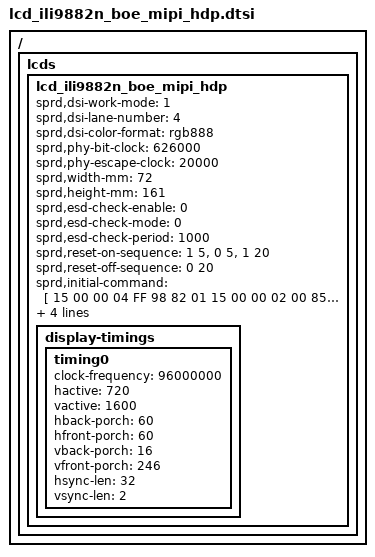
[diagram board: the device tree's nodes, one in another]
/ { lcds {
    lcd_ili9882n_boe_mipi_hdp: lcd_ili9882n_boe_mipi_hdp {

        sprd,dsi-work-mode = <1>;
        sprd,dsi-lane-number = <4>;
        sprd,dsi-color-format = "rgb888";

        sprd,phy-bit-clock = <626000>;
        sprd,phy-escape-clock = <20000>;

        sprd,width-mm = <72>;
        sprd,height-mm = <161>;

        sprd,esd-check-enable = <0>;
        sprd,esd-check-mode = <0>;
        sprd,esd-check-period = <1000>;

        sprd,reset-on-sequence = <1 5>, <0 5>, <1 20>;
        sprd,reset-off-sequence = <0 20>;

        sprd,initial-command = [

            15  00  00  04 FF 98 82 01
            15  00  00  02 00 85
            15  00  00  02 01 32
            15  00  00  02 02 2A
            15  00  00  02 03 05
            15  00  00  02 04 C9
            15  00  00  02 05 32
            15  00  00  02 06 2A
            15  00  00  02 07 05
            15  00  00  02 08 85
            15  00  00  02 09 02
            15  00  00  02 0A 72
            15  00  00  02 0B 00
            15  00  00  02 28 00
            15  00  00  02 29 00
            15  00  00  02 EE 17
            15  00  00  02 2A 85
            15  00  00  02 2B 4A
            15  00  00  02 F0 37
            15  00  00  02 E0 7E
            15  00  00  02 31 07
            15  00  00  02 32 07
            15  00  00  02 33 07
            15  00  00  02 34 07
            15  00  00  02 35 00
            15  00  00  02 36 07
            15  00  00  02 37 01
            15  00  00  02 38 22
            15  00  00  02 39 23
            15  00  00  02 3A 07
            15  00  00  02 3B 10
            15  00  00  02 3C 12
            15  00  00  02 3D 14
            15  00  00  02 3E 16
            15  00  00  02 3F 07
            15  00  00  02 40 0C
            15  00  00  02 41 0E
            15  00  00  02 42 07
            15  00  00  02 43 07
            15  00  00  02 44 07
            15  00  00  02 45 07
            15  00  00  02 46 07
            15  00  00  02 47 07
            15  00  00  02 48 07
            15  00  00  02 49 07
            15  00  00  02 4A 07
            15  00  00  02 4B 00
            15  00  00  02 4C 07
            15  00  00  02 4D 01
            15  00  00  02 4E 22
            15  00  00  02 4F 23
            15  00  00  02 50 07
            15  00  00  02 51 11
            15  00  00  02 52 13
            15  00  00  02 53 15
            15  00  00  02 54 17
            15  00  00  02 55 07
            15  00  00  02 56 0D
            15  00  00  02 57 0F
            15  00  00  02 58 07
            15  00  00  02 59 07
            15  00  00  02 5A 07
            15  00  00  02 5B 07
            15  00  00  02 5C 07
            15  00  00  02 61 07
            15  00  00  02 62 07
            15  00  00  02 63 07
            15  00  00  02 64 07
            15  00  00  02 65 00
            15  00  00  02 66 07
            15  00  00  02 67 01
            15  00  00  02 68 22
            15  00  00  02 69 23
            15  00  00  02 6A 07
            15  00  00  02 6B 17
            15  00  00  02 6C 15
            15  00  00  02 6D 13
            15  00  00  02 6E 11
            15  00  00  02 6F 07
            15  00  00  02 70 0F
            15  00  00  02 71 0D
            15  00  00  02 72 07
            15  00  00  02 73 07
            15  00  00  02 74 07
            15  00  00  02 75 07
            15  00  00  02 76 07
            15  00  00  02 77 07
            15  00  00  02 78 07
            15  00  00  02 79 07
            15  00  00  02 7A 07
            15  00  00  02 7B 00
            15  00  00  02 7C 07
            15  00  00  02 7D 01
            15  00  00  02 7E 22
            15  00  00  02 7F 23
            15  00  00  02 80 07
            15  00  00  02 81 16
            15  00  00  02 82 14
            15  00  00  02 83 12
            15  00  00  02 84 10
            15  00  00  02 85 07
            15  00  00  02 86 0E
            15  00  00  02 87 0C
            15  00  00  02 88 07
            15  00  00  02 89 07
            15  00  00  02 8A 07
            15  00  00  02 8B 07
            15  00  00  02 8C 07
            15  00  00  02 A0 01
            15  00  00  02 A1 00
            15  00  00  02 A2 00
            15  00  00  02 A3 00
            15  00  00  02 A4 00
            15  00  00  02 A7 00
            15  00  00  02 A8 00
            15  00  00  02 A9 00
            15  00  00  02 AA 00
            15  00  00  02 B0 34
            15  00  00  02 B2 04
            15  00  00  02 B9 10
            15  00  00  02 BA 02
            15  00  00  02 C1 10
            15  00  00  02 D0 01
            15  00  00  02 D1 10
            15  00  00  02 D2 40
            15  00  00  02 D5 56
            15  00  00  02 D6 91
            15  00  00  02 Dc 40
            15  00  00  02 E2 42
            15  00  00  02 E6 31
            15  00  00  02 EA 0F
            15  00  00  02 E7 54

            15  00  00  04 FF 98 82 02
            15  00  00  02 F1 1C
            15  00  00  02 4B 5A
            15  00  00  02 50 CA
            15  00  00  02 51 00
            15  00  00  02 06 8B
            15  00  00  02 0B A0
            15  00  00  02 0C 80
            15  00  00  02 0D 1A
            15  00  00  02 0E 09
            15  00  00  02 4E 11
            15  00  00  02 01 14
            15  00  00  02 02 0A

            15  00  00  04 FF 98 82 05
            15  00  00  02 03 01
            15  00  00  02 04 22
            15  00  00  02 58 61
            15  00  00  02 63 88
            15  00  00  02 64 88
            15  00  00  02 68 B5
            15  00  00  02 69 BB
            15  00  00  02 6A 8D
            15  00  00  02 6B 7F
            15  00  00  02 85 77
            15  00  00  02 47 0A
            15  00  00  02 C8 F1
            15  00  00  02 C9 F1
            15  00  00  02 CA B5
            15  00  00  02 CB B5
            15  00  00  02 D0 F7
            15  00  00  02 D1 F7
            15  00  00  02 D2 BB
            15  00  00  02 D3 BB
            15  00  00  02 46 00

            15  00  00  04 FF 98 82 06
            15  00  00  02 D9 1F
            15  00  00  02 08 00
            15  00  00  02 C0 40
            15  00  00  02 C1 16

            15  00  00  04 FF 98 82 07
            15  00  00  02 C0 01
            15  00  00  02 CB C0
            15  00  00  02 CC BB
            15  00  00  02 CD 83
            15  00  00  02 CE 83

            15  00  00  04 FF 98 82 08
            15  00  00  1c E0 00 24 4B 6E 9F 50 CB F1 1F 45 95 84 B8 E8 17 AA 48 84 A9 D7 FE FD 2E 68 97 03 EC
            15  00  00  1c E1 00 24 4B 6E 9F 50 CB F1 1F 45 95 84 B8 E8 17 AA 48 84 A9 D7 FE FD 2E 68 97 03 EC

            15  00  00  04 FF 98 82 0B
            15  00  00  02 9A 44
            15  00  00  02 9B 78
            15  00  00  02 9C 03
            15  00  00  02 9D 03
            15  00  00  02 9E 70
            15  00  00  02 9F 70
            15  00  00  02 AB E0

            15  00  00  04 FF 98 82 0E
            15  00  00  02 11 10
            15  00  00  02 13 10
            15  00  00  02 00 A0

            15  00  00  04 FF 98 82 00
            15  00  00  02  35 00
            15  78  00  02  11 00
            15  64  00  02  29 00
        ];
        sprd,sleep-in-command = [
            13 0A 00 01 28
            13 78 00 01 10
        ];
        sprd,sleep-out-command = [
            13 78 00 01 11
            13 32 00 01 29
        ];

        display-timings {
            timing0 {
                clock-frequency = <96000000>;
                hactive = <720>;
                vactive = <1600>;
                hback-porch = <60>;
                hfront-porch = <60>;
                vback-porch = <16>;
                vfront-porch = <246>;
                hsync-len = <32>;
                vsync-len = <2>;
            };
        };
    };
};};

